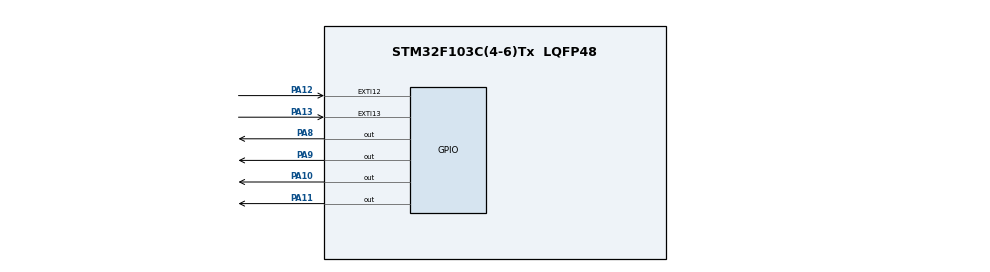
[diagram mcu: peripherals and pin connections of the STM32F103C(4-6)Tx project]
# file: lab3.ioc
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Mcu.Family=STM32F1
PA13.GPIO_ModeDefaultEXTI=GPIO_MODE_IT_FALLING
PA12.GPIO_ModeDefaultEXTI=GPIO_MODE_IT_FALLING
VP_SYS_VS_ND.Mode=No_Debug
ProjectManager.StackSize=0x400
PA13.Signal=GPXTI13
PA12.Signal=GPXTI12
ProjectManager.TargetToolchain=STM32CubeIDE
PA9.Signal=GPIO_Output
NVIC.EXTI15_10_IRQn=true\:0\:0\:false\:true\:true\:1\:true\:true
board=custom
PA13.GPIO_PuPd=GPIO_NOPULL
RCC.APB2Freq_Value=8000000
PA8.Signal=GPIO_Output
Mcu.Name=STM32F103C(4-6)Tx
Mcu.Package=LQFP48
PA11.Signal=GPIO_Output
PA10.Signal=GPIO_Output
ProjectManager.HeapSize=0x200
NVIC.PriorityGroup=NVIC_PRIORITYGROUP_4
PA12.GPIO_PuPd=GPIO_NOPULL
RCC.APB1Freq_Value=8000000

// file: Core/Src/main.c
/* USER CODE BEGIN Header */
/**
  ******************************************************************************
  * @file           : main.c
  * @brief          : Main program body
  ******************************************************************************
  * @attention
  *
  * <h2><center>&copy; Copyright (c) 2021 STMicroelectronics.
  * All rights reserved.</center></h2>
  *
  * This software component is licensed by ST under BSD 3-Clause license,
  * the "License"; You may not use this file except in compliance with the
  * License. You may obtain a copy of the License at:
  *                        opensource.org/licenses/BSD-3-Clause
  *
  ******************************************************************************
  */
/* USER CODE END Header */
#include "main.h"

/* USER CODE BEGIN PV */
const uint16_t pins[] = {GPIO_PIN_11,GPIO_PIN_10,GPIO_PIN_9,GPIO_PIN_8};
const int size = sizeof(pins)/sizeof(pins[0]);
/* USER CODE END PV */

void SystemClock_Config(void);
static void MX_GPIO_Init(void);
static void MX_NVIC_Init(void);

int main(void)
{

  /* MCU Configuration--------------------------------------------------------*/

  /* Reset of all peripherals, Initializes the Flash interface and the Systick. */
  HAL_Init();

  /* Configure the system clock */
  SystemClock_Config();

  /* Initialize all configured peripherals */
  MX_GPIO_Init();

  /* Initialize interrupts */
  MX_NVIC_Init();

  /* Infinite loop */
  while (1)
  {

  }
}

void SystemClock_Config(void)
{
  RCC_OscInitTypeDef RCC_OscInitStruct = {0};
  RCC_ClkInitTypeDef RCC_ClkInitStruct = {0};

  /** Initializes the RCC Oscillators according to the specified parameters
  * in the RCC_OscInitTypeDef structure.
  */
  RCC_OscInitStruct.OscillatorType = RCC_OSCILLATORTYPE_HSI;
  RCC_OscInitStruct.HSIState = RCC_HSI_ON;
  RCC_OscInitStruct.HSICalibrationValue = RCC_HSICALIBRATION_DEFAULT;
  RCC_OscInitStruct.PLL.PLLState = RCC_PLL_NONE;
  if (HAL_RCC_OscConfig(&RCC_OscInitStruct) != HAL_OK)
  {
    Error_Handler();
  }
  /** Initializes the CPU, AHB and APB buses clocks
  */
  RCC_ClkInitStruct.ClockType = RCC_CLOCKTYPE_HCLK|RCC_CLOCKTYPE_SYSCLK
                              |RCC_CLOCKTYPE_PCLK1|RCC_CLOCKTYPE_PCLK2;
  RCC_ClkInitStruct.SYSCLKSource = RCC_SYSCLKSOURCE_HSI;
  RCC_ClkInitStruct.AHBCLKDivider = RCC_SYSCLK_DIV1;
  RCC_ClkInitStruct.APB1CLKDivider = RCC_HCLK_DIV1;
  RCC_ClkInitStruct.APB2CLKDivider = RCC_HCLK_DIV1;

  if (HAL_RCC_ClockConfig(&RCC_ClkInitStruct, FLASH_LATENCY_0) != HAL_OK)
  {
    Error_Handler();
  }
}

/**
  * @brief NVIC Configuration.
  * @retval None
  */
static void MX_NVIC_Init(void)
{
  /* EXTI15_10_IRQn interrupt configuration */
  HAL_NVIC_SetPriority(EXTI15_10_IRQn, 0, 0);
  HAL_NVIC_EnableIRQ(EXTI15_10_IRQn);
}

static void MX_GPIO_Init(void)
{
  GPIO_InitTypeDef GPIO_InitStruct = {0};

  /* GPIO Ports Clock Enable */
  __HAL_RCC_GPIOA_CLK_ENABLE();

  /*Configure GPIO pin Output Level */
  HAL_GPIO_WritePin(GPIOA, GPIO_PIN_8|GPIO_PIN_9|GPIO_PIN_10|GPIO_PIN_11, GPIO_PIN_RESET);

  /*Configure GPIO pins : PA8 PA9 PA10 PA11 */
  GPIO_InitStruct.Pin = GPIO_PIN_8|GPIO_PIN_9|GPIO_PIN_10|GPIO_PIN_11;
  GPIO_InitStruct.Mode = GPIO_MODE_OUTPUT_PP;
  GPIO_InitStruct.Pull = GPIO_NOPULL;
  GPIO_InitStruct.Speed = GPIO_SPEED_FREQ_LOW;
  HAL_GPIO_Init(GPIOA, &GPIO_InitStruct);

  /*Configure GPIO pins : PA12 PA13 */
  GPIO_InitStruct.Pin = GPIO_PIN_12|GPIO_PIN_13;
  GPIO_InitStruct.Mode = GPIO_MODE_IT_FALLING;
  GPIO_InitStruct.Pull = GPIO_NOPULL;
  HAL_GPIO_Init(GPIOA, &GPIO_InitStruct);

}

/* USER CODE BEGIN 4 */
void HAL_GPIO_EXTI_Callback(uint16_t GPIO_Pin)
{
	if(GPIO_Pin == GPIO_PIN_12)
	{
		for(int i = 0;i<size;i++)
		{
			if(HAL_GPIO_ReadPin(GPIOA, pins[i]) == GPIO_PIN_RESET)
			{
				  HAL_GPIO_WritePin(GPIOA, pins[i], GPIO_PIN_SET);
				  break;
			}
		}
	}

	if(GPIO_Pin == GPIO_PIN_13)
	{
		for(int i = 0;i<size;i++)
		{
			if(HAL_GPIO_ReadPin(GPIOA, pins[i]) == GPIO_PIN_SET)
			{
				  HAL_GPIO_WritePin(GPIOA, pins[i], GPIO_PIN_RESET);
				  break;
			}
		}
	}
}
/* USER CODE END 4 */

void Error_Handler(void)
{
  __disable_irq();
  while (1)
  {
  }
}

/************************ (C) COPYRIGHT STMicroelectronics *****END OF FILE****/
